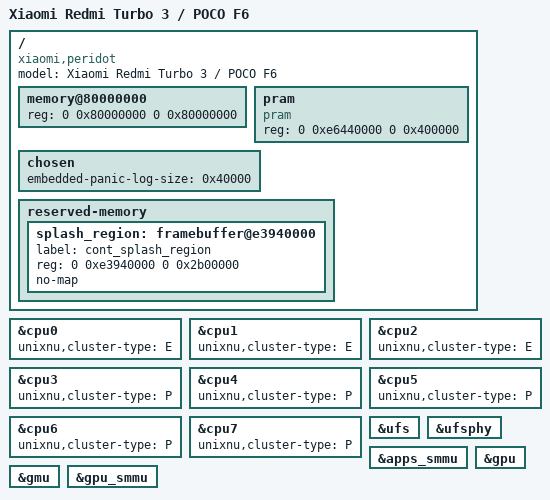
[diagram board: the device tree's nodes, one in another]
// SPDX-License-Identifier: BSD-3-Clause
// Board DTS for the Redmi Turbo 3 / POCO F6 (peridot, Qualcomm SM8635 "cliffs").
//
// This is the small hand-written board description consumed by the ADT
// generator. The vendor dump that ships with the phone lives in
// dts/vendor/peridot-stock.dts and is a reference, not an input.
/dts-v1/;
/include/ "sm8635.dtsi"

/ {
    model = "Xiaomi Redmi Turbo 3 / POCO F6";
    compatible = "xiaomi,peridot", "qcom,cliffs-mtp", "qcom,cliffs", "qcom,sm8635";

    // XNU owns the low 2 GiB window starting at 0x80000000. The phone has
    // 12 GiB physically, but the firmware memory map and ADT expose only this
    // contiguous window. Keep this value equal to payload.dram_size.
    memory@80000000 {
        device_type = "memory";
        reg = <0 0x80000000 0 0x80000000>;
    };

    // Persistent panic log (pexpert check_for_panic_log): XNU maps /pram and keeps the
    // last panic text in /chosen's embedded-panic-log-size window. patched
    // peridot-last-panic-print.patch prints it on the next boot. The stock
    // ramoops at 0xa7000000 overlaps the Mu-Silicium UEFI FD (0xa7100000 +
    // 0x300000); use the gap immediately above Display_Reserved instead.
    // TODO(verify): confirm this range is not allocated by UEFI on next boot.
    pram {
        compatible = "pram";
        reg = <0 0xe6440000 0 0x400000>;
    };

    chosen {
        embedded-panic-log-size = <0x40000>;
    };

    reserved-memory {
        #address-cells = <2>;
        #size-cells = <2>;
        ranges;

        // Display_Reserved in the Mu-Silicium peridot memory map.
        splash_region: framebuffer@e3940000 {
            label = "cont_splash_region";
            reg = <0 0xe3940000 0 0x2b00000>;
            no-map;
        };
    };
};

// A520 cores run as the E cluster, A720 and the X4 as the P cluster.
&cpu0 { unixnu,cluster-type = "E"; };
&cpu1 { unixnu,cluster-type = "E"; };
&cpu2 { unixnu,cluster-type = "E"; };
&cpu3 { unixnu,cluster-type = "P"; };
&cpu4 { unixnu,cluster-type = "P"; };
&cpu5 { unixnu,cluster-type = "P"; };
&cpu6 { unixnu,cluster-type = "P"; };
&cpu7 { unixnu,cluster-type = "P"; };

// Storage is described but has no driver yet; see the storage area of porting.toml.
&ufs { status = "okay"; };
&ufsphy { status = "okay"; };
&apps_smmu { status = "okay"; };

// GPU bring-up: the platform publishes an IOPlatformDevice for each of these, and
// NativeAdreno735 claims only the node at 0x3d00000. Enabled so the ADT carries them.
&gpu { status = "okay"; };
&gmu { status = "okay"; };
&gpu_smmu { status = "okay"; };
